# SPINLOCK_SPINLOCK_50E00000h register map
Vendor: Texas Instruments
Peripheral module from a debugger description file (folder AM261x).
Registers are 32-bit, read-only, reset 0x0 unless marked. A register's access mark holds for its fields unless they carry their own. Offsets are as the file gives them; lines under a group give offsets from that group; [hi:lo] are bit positions; {n}, {i} and the like mark numbered series; 'fields as' and 'values as' point back to an identical list; <NAME> marks a mode.

## SPINLOCK
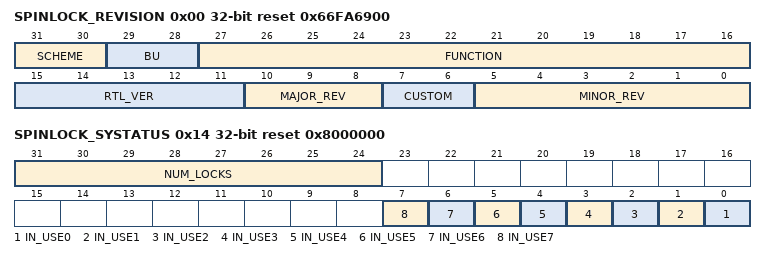
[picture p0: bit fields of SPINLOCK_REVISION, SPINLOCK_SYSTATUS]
0x00 SPINLOCK_REVISION reset 0x66FA6900 — This is the standard TI peripheral ID register that exists at address 0 in the peripheral space.
  [31:30] SCHEME — Used to distinguish which ID numbering scheme is used.
  [29:28] BU — BU identifier
  [27:16] FUNCTION — Module family.
  [15:11] RTL_VER — RTL version. R of X.Y.R.Z
  [10:8] MAJOR_REV — Major revision. X of X.Y.R.Z
  [7:6] CUSTOM — Special version number
  [5:0] MINOR_REV — Minor revision. Y of X.Y.R.Z
0x10 SPINLOCK_SYSCONFIG rw — Provides the SOFTRESET register for backwards compatibility with OMAP Spinlock.
  [1] SOFT_RESET — Module Software ResetThe bit is automatically reset by the hardware. During reads, it always returns 0It has the same effect as the hardware resetWriting a 0 has no effect. Writing a 1 will start a soft reset sequence and free all of the locks
0x14 SPINLOCK_SYSTATUS reset 0x8000000 — Provides information about the Spinlock module.
  [31:24] NUM_LOCKS — Module configuration parameter n, the total number of spinlocks divided by 32.e.g. For 256 spin locks, this will return the number 0x08
  [n] IN_USE{n} (n=0..7) — In-Use flag {n} covering lock registers {32n} - {32n+31}.If no lock registers are implemented in this range, then this flag always reads as 0Read0 : All lock registers {32n} - {32n+31} are in the Not Taken stateRead1 : At least one of the lock registers {32n} - {32n+31} are in the Taken state
0x800 SPINLOCK_LOCK_REG_j rw — The Lock[a] register is read and written to perform lock and unlock operations on lock 'a'.
  [0] TAKEN — Lock StatusRead0 : Lock was previously free. The reader now has been granted the lock.Read1 : Lock was previously taken. The reader has not been granted the lock and must retry.Write0 : Free the lock by setting TAKEN to zero.Write1 : No effect
